AUTOSAR XML (schema 314)
package /ComponentType
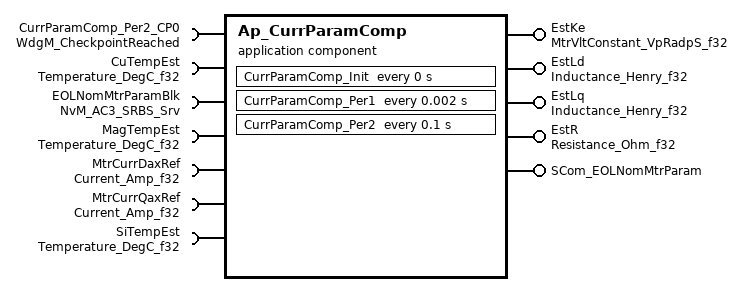
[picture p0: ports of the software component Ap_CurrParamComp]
  application software component type Ap_CurrParamComp
    5 x provide port:
      EstKe: unqueued-sender-com-spec{data-element=VpRadpS_f32, can-invalidate=false, init-value=D_ZERO_ULS_F32}, provided-interface=MtrVltConstant_VpRadpS_f32
      EstLd: unqueued-sender-com-spec{data-element=Henry_f32, can-invalidate=false, init-value=D_ZERO_ULS_F32}, provided-interface=Inductance_Henry_f32
      EstLq: unqueued-sender-com-spec{data-element=Henry_f32, can-invalidate=false, init-value=D_ZERO_ULS_F32}, provided-interface=Inductance_Henry_f32
      EstR: unqueued-sender-com-spec{data-element=Ohm_f32, can-invalidate=false, init-value=D_ZERO_ULS_F32}, provided-interface=Resistance_Ohm_f32
      SCom_EOLNomMtrParam: provided-com-specs=[{operation=Get, queue-length=1}, {operation=Set, queue-length=1}], provided-interface=SCom_EOLNomMtrParam
    7 x require port:
      CurrParamComp_Per2_CP0: client-com-spec=CheckpointReached, required-interface=WdgM_CheckpointReached
      CuTempEst: unqueued-receiver-com-spec{data-element=DegC_f32, init-value=D_ZERO_ULS_F32}, required-interface=Temperature_DegC_f32
      EOLNomMtrParamBlk: required-com-specs=[EraseBlock, GetErrorStatus, InvalidateNvBlock, ReadBlock, SetRamBlockStatus, WriteBlock], required-interface=NvM_AC3_SRBS_Srv
      MagTempEst: unqueued-receiver-com-spec{data-element=DegC_f32, init-value=D_ZERO_ULS_F32}, required-interface=Temperature_DegC_f32
      MtrCurrDaxRef: unqueued-receiver-com-spec{data-element=Amp_f32, init-value=D_ZERO_ULS_F32}, required-interface=Current_Amp_f32
      MtrCurrQaxRef: unqueued-receiver-com-spec{data-element=Amp_f32, init-value=D_ZERO_ULS_F32}, required-interface=Current_Amp_f32
      SiTempEst: unqueued-receiver-com-spec{data-element=DegC_f32, init-value=D_ZERO_ULS_F32}, required-interface=Temperature_DegC_f32
  internal behavior Ap_CurrParamComp_InternalBehavior: component=Ap_CurrParamComp
    timing event CurrParamComp_InitEvent: start-on-event=CurrParamComp_Init, period=0
    timing event TMT_CurrParamComp_Per1: start-on-event=CurrParamComp_Per1, period=0.002
    timing event TMT_CurrParamComp_Per2: start-on-event=CurrParamComp_Per2, period=0.1
    operation invoked event OIT_SCom_EOLNomMtrParam_Get_SCom_EOLNomMtrParam_Get: start-on-event=SCom_EOLNomMtrParam_Get, operation=SCom_EOLNomMtrParam.Get
    operation invoked event OIT_SCom_EOLNomMtrParam_Set_SCom_EOLNomMtrParam_Set: start-on-event=SCom_EOLNomMtrParam_Set, operation=SCom_EOLNomMtrParam.Set
    per instance memory EOLNomMtrParam: type=EOLNomMtrParamType, type-definition=/DataType/EOLNomMtrParamType
    port-api-options:
      enable-take-address=false, indirect-api=false, port=CurrParamComp_Per2_CP0
      enable-take-address=false, indirect-api=false, port=CuTempEst
      enable-take-address=false, indirect-api=false, port=EOLNomMtrParamBlk
      enable-take-address=false, indirect-api=false, port=EstKe
      enable-take-address=false, indirect-api=false, port=EstLd
      enable-take-address=false, indirect-api=false, port=EstLq
      enable-take-address=false, indirect-api=false, port=EstR
      enable-take-address=false, indirect-api=false, port=MagTempEst
      enable-take-address=false, indirect-api=false, port=MtrCurrDaxRef
      enable-take-address=false, indirect-api=false, port=MtrCurrQaxRef
      enable-take-address=false, indirect-api=false, port=SCom_EOLNomMtrParam
      enable-take-address=false, indirect-api=false, port=SiTempEst
    5 x runnable:
      CurrParamComp_Init
        4 x data write access:
          WRITE_EstKe_VpRadpS_f32: data-element=EstKe.VpRadpS_f32
          WRITE_EstLd_Henry_f32: data-element=EstLd.Henry_f32
          WRITE_EstLq_Henry_f32: data-element=EstLq.Henry_f32
          WRITE_EstR_Ohm_f32: data-element=EstR.Ohm_f32
      CurrParamComp_Per1
        data read access READ_MtrCurrDaxRef_Amp_f32: data-element=MtrCurrDaxRef.Amp_f32
        data read access READ_MtrCurrQaxRef_Amp_f32: data-element=MtrCurrQaxRef.Amp_f32
        4 x data write access:
          WRITE_EstKe_VpRadpS_f32: data-element=EstKe.VpRadpS_f32
          WRITE_EstLd_Henry_f32: data-element=EstLd.Henry_f32
          WRITE_EstLq_Henry_f32: data-element=EstLq.Henry_f32
          WRITE_EstR_Ohm_f32: data-element=EstR.Ohm_f32
      CurrParamComp_Per2
        data read access READ_CuTempEst_DegC_f32: data-element=CuTempEst.DegC_f32
        data read access READ_MagTempEst_DegC_f32: data-element=MagTempEst.DegC_f32
        data read access READ_SiTempEst_DegC_f32: data-element=SiTempEst.DegC_f32
        sync call SC_CurrParamComp_Per2_CP0_CheckpointReached: operation=CurrParamComp_Per2_CP0.CheckpointReached, timeout=0
      SCom_EOLNomMtrParam_Get
      SCom_EOLNomMtrParam_Set
        sync call SC_EOLNomMtrParamBlk_WriteBlock: operation=EOLNomMtrParamBlk.WriteBlock, timeout=0
    service-needss:
      swc nv block needs EOLNomMtrParamBlk: n-data-sets=0, readonly=false, reliability=LOW, resistant-to-changed-sw=false, restore-at-start=false, write-only-once=false, writing-frequency=0, writing-priority=LOW, mirror-block=EOLNomMtrParam
  swc implementation Ap_CurrParamComp_Implementation: behavior=Ap_CurrParamComp_InternalBehavior
    code-descriptors:
      code Code: type=SRC
